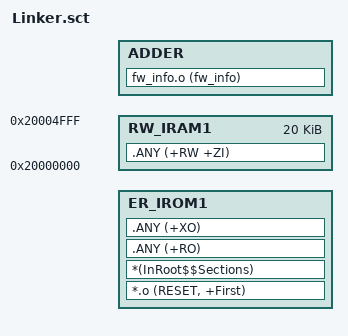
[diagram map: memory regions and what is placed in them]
#! armcc -E -I./
; *************************************************************
; *** Scatter-Loading Description File generated by uVision ***
; *************************************************************
#include "../../General/mapping_cfg.h"

LR_IROM1 MAP_MAIN_ADDR_START MAP_MAIN_SIZE  {    ; load region size_region
  ER_IROM1 MAP_MAIN_ADDR_START MAP_MAIN_SIZE  {  ; load address = execution address
   *.o (RESET, +First)
   *(InRoot$$Sections)
   .ANY (+RO)
   .ANY (+XO)
  }
  RW_IRAM1 0x20000000 0x00005000  {  ; RW data
   .ANY (+RW +ZI)
  }
}

FLASH MAP_MAIN_ADDR_START+MAP_MAIN_SIZE-0x20 ;size of fw_info
{
  ADDER MAP_MAIN_ADDR_START+MAP_MAIN_SIZE-0x20
  {
    fw_info.o (fw_info)                  ; select section foo from file.o
  }
}
